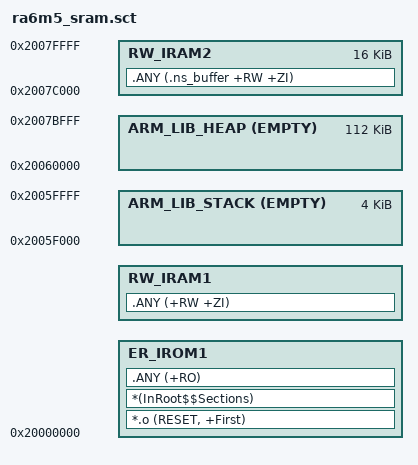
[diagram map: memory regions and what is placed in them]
;***************************************************************
;* RA6M5 linker scatter file (running code from internal SRAM) *
;***************************************************************

LR_IROM1 0x20000000 0x80000
{
   ER_IROM1 0x20000000
   {
      *.o (RESET, +First)
      *(InRoot$$Sections)
      .ANY (+RO)
   }
   
   RW_IRAM1 +0
   { 
      .ANY (+RW +ZI)
   }
   
   ScatterAssert((ImageLength(ER_IROM1) + ImageLength(RW_IRAM1)) < 0x5F000)
   
   ARM_LIB_STACK 0x20060000 EMPTY -0x1000
   {
   }
   
   ARM_LIB_HEAP 0x20060000 EMPTY 0x1C000
   {
   }
   
   RW_IRAM2 0x2007C000 0x4000
   {
      .ANY (.ns_buffer +RW +ZI)
   }
}
